VERSION ""

NS_ :

BS_:

BU_: IG_Node

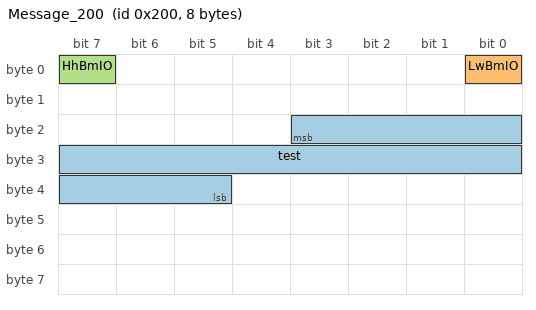
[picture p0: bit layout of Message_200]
BO_ 512 Message_200: 8 Vector__XXX
 SG_ test : 19|15@0+ (1,0) [0|32767] "" Vector__XXX
 SG_ LwBmIO : 0|1@0+ (1,0) [0|1] "" Vector__XXX
 SG_ HhBmIO : 7|1@0+ (1,0) [0|1] "" Vector__XXX

BA_DEF_  "BusType" STRING ;
BA_DEF_DEF_  "BusType" "CAN";
